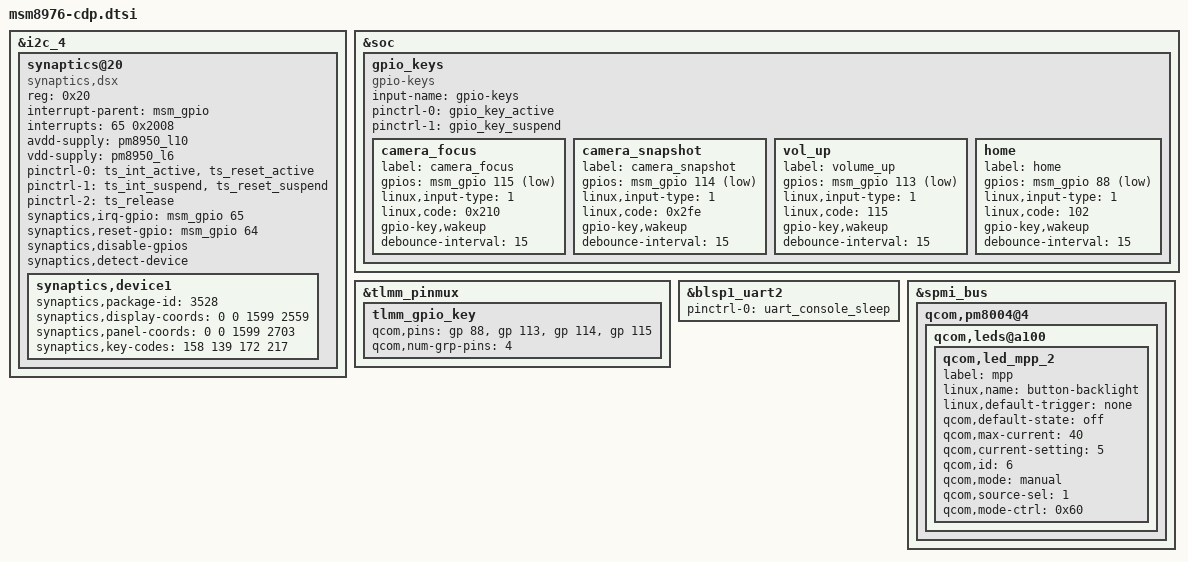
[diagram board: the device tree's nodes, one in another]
/*
 * Copyright (c) 2015, The Linux Foundation. All rights reserved.
 *
 * This program is free software; you can redistribute it and/or modify
 * it under the terms of the GNU General Public License version 2 and
 * only version 2 as published by the Free Software Foundation.
 *
 * This program is distributed in the hope that it will be useful,
 * but WITHOUT ANY WARRANTY; without even the implied warranty of
 * MERCHANTABILITY or FITNESS FOR A PARTICULAR PURPOSE.  See the
 * GNU General Public License for more details.
 */

#include "msm8976.dtsi"
#include "msm8976-pinctrl.dtsi"

&i2c_4 { /* BLSP1 QUP4 */
	synaptics@20 {
		compatible = "synaptics,dsx";
		reg = <0x20>;
		interrupt-parent = <&msm_gpio>;
		interrupts = <65 0x2008>;
		avdd-supply = <&pm8950_l10>;
		vdd-supply = <&pm8950_l6>;
		/* pins used by touchscreen */
		pinctrl-names = "pmx_ts_active","pmx_ts_suspend","pmx_ts_release";
		pinctrl-0 = <&ts_int_active &ts_reset_active>;
		pinctrl-1 = <&ts_int_suspend &ts_reset_suspend>;
		pinctrl-2 = <&ts_release>;
		synaptics,irq-gpio = <&msm_gpio 65 0x2008>;
		synaptics,reset-gpio = <&msm_gpio 64 0x0>;
		synaptics,disable-gpios;
		synaptics,detect-device;
		synaptics,device1 {
			synaptics,package-id = <3528>;
			synaptics,display-coords = <0 0 1599 2559>;
			synaptics,panel-coords = <0 0 1599 2703>;
			synaptics,key-codes = <158 139 172 217>;
		};
	};
};

&soc {
	gpio_keys {
		compatible = "gpio-keys";
		input-name = "gpio-keys";
		pinctrl-names = "tlmm_gpio_key_active","tlmm_gpio_key_suspend";
		pinctrl-0 = <&gpio_key_active>;
		pinctrl-1 = <&gpio_key_suspend>;

		camera_focus {
			label = "camera_focus";
			gpios = <&msm_gpio 115 0x1>;
			linux,input-type = <1>;
			linux,code = <0x210>;
			gpio-key,wakeup;
			debounce-interval = <15>;
		};

		camera_snapshot {
			label = "camera_snapshot";
			gpios = <&msm_gpio 114 0x1>;
			linux,input-type = <1>;
			linux,code = <0x2fe>;
			gpio-key,wakeup;
			debounce-interval = <15>;
		};

		vol_up {
			label = "volume_up";
			gpios = <&msm_gpio 113 0x1>;
			linux,input-type = <1>;
			linux,code = <115>;
			gpio-key,wakeup;
			debounce-interval = <15>;
		};

		home {
			label = "home";
			gpios = <&msm_gpio 88 0x1>;
			linux,input-type = <1>;
			linux,code = <102>;
			gpio-key,wakeup;
			debounce-interval = <15>;
		};
	};
};

&tlmm_pinmux {
	tlmm_gpio_key {
		qcom,pins = <&gp 88>, <&gp 113>, <&gp 114>, <&gp 115>;
		qcom,num-grp-pins = <4>;
	};
};

&blsp1_uart2 {
	status = "ok";
	pinctrl-names = "default";
	pinctrl-0 = <&uart_console_sleep>;
};


&spmi_bus {
	qcom,pm8004@4 {
		qcom,leds@a100 {
			status = "okay";
			qcom,led_mpp_2 {
				label = "mpp";
				linux,name = "button-backlight";
				linux,default-trigger = "none";
				qcom,default-state = "off";
				qcom,max-current = <40>;
				qcom,current-setting = <5>;
				qcom,id = <6>;
				qcom,mode = "manual";
				qcom,source-sel = <1>;
				qcom,mode-ctrl = <0x60>;
			};
		};
	};
};

